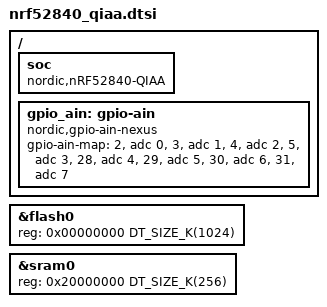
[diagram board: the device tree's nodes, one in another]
/*
 * Copyright (c) 2018 Linaro Limited
 *
 * SPDX-License-Identifier: Apache-2.0
 */

#include <mem.h>
#include <nordic/nrf52840.dtsi>

&flash0 {
	reg = <0x00000000 DT_SIZE_K(1024)>;
};

&sram0 {
	reg = <0x20000000 DT_SIZE_K(256)>;
};

/ {
	soc {
		compatible = "nordic,nRF52840-QIAA", "nordic,nRF52840", "nordic,nRF52", "simple-bus";
	};

	gpio_ain: gpio-ain {
		compatible = "nordic,gpio-ain-nexus";
#if 0
		#gpio-ain-cells = <2>;
		gpio-ain-map =
			<&gpio0 2 &adc 0>,
			<&gpio0 3 &adc 1>,
			<&gpio0 4 &adc 2>,
			<&gpio0 5 &adc 3>,
			<&gpio0 28 &adc 4>,
			<&gpio0 29 &adc 5>,
			<&gpio0 30 &adc 6>,
			<&gpio0 31 &adc 7>;
#else
		#gpio-ain-cells = <1>;

		gpio-ain-map =
			<2 &adc 0>,
			<3 &adc 1>,
			<4 &adc 2>,
			<5 &adc 3>,
			<28 &adc 4>,
			<29 &adc 5>,
			<30 &adc 6>,
			<31 &adc 7>;
#endif
	};
};
